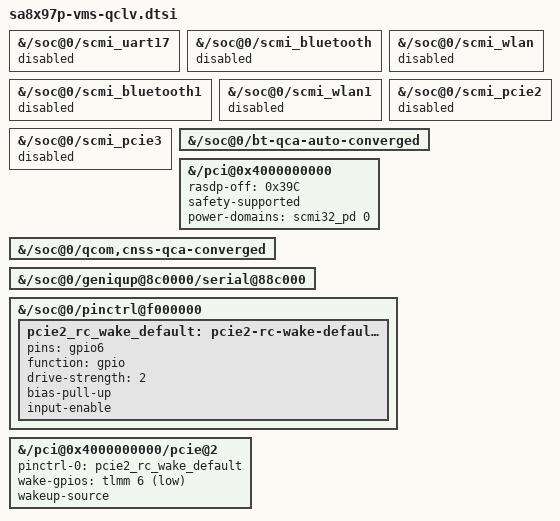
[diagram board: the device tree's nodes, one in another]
// SPDX-License-Identifier: BSD-3-Clause
/*
* Copyright (c) Qualcomm Technologies, Inc. and/or its subsidiaries.
*/

#include <dt-bindings/gpio/gpio.h>
#include "sa8x97p-vms-lv.dtsi"

&{/soc@0/scmi_uart17} {
	status = "disabled";
};

&{/soc@0/scmi_bluetooth} {
	status = "disabled";
};

&{/soc@0/scmi_bluetooth1} {
	status = "disabled";
};

&{/soc@0/scmi_wlan} {
	status = "disabled";
};

&{/soc@0/scmi_wlan1} {
	status = "disabled";
};

&{/soc@0/scmi_pcie2} {
	status = "disabled";
};

&{/soc@0/scmi_pcie3} {
	status = "disabled";
};

&{/soc@0/bt-qca-auto-converged} {
	status = "ok";
};

&{/pci@0x4000000000} {
	status = "ok";
	rasdp-off = <0x39C>;
	safety-supported;
	power-domains = <&scmi32_pd 0>;
	power-domain-names = "power";
};

&{/soc@0/qcom,cnss-qca-converged} {
	status = "ok";
};

&{/soc@0/geniqup@8c0000/serial@88c000} {
	status = "ok";
};

&{/soc@0/pinctrl@f000000} {
	pcie2_rc_wake_default: pcie2-rc-wake-default-state {
		pins = "gpio6";
		function = "gpio";
		drive-strength = <2>;
		bias-pull-up;
		input-enable;
	};
};

&{/pci@0x4000000000/pcie@2} {
	pinctrl-names = "default";
	pinctrl-0 = <&pcie2_rc_wake_default>;
	wake-gpios = <&tlmm 6 GPIO_ACTIVE_LOW>;
	wakeup-source;
};
